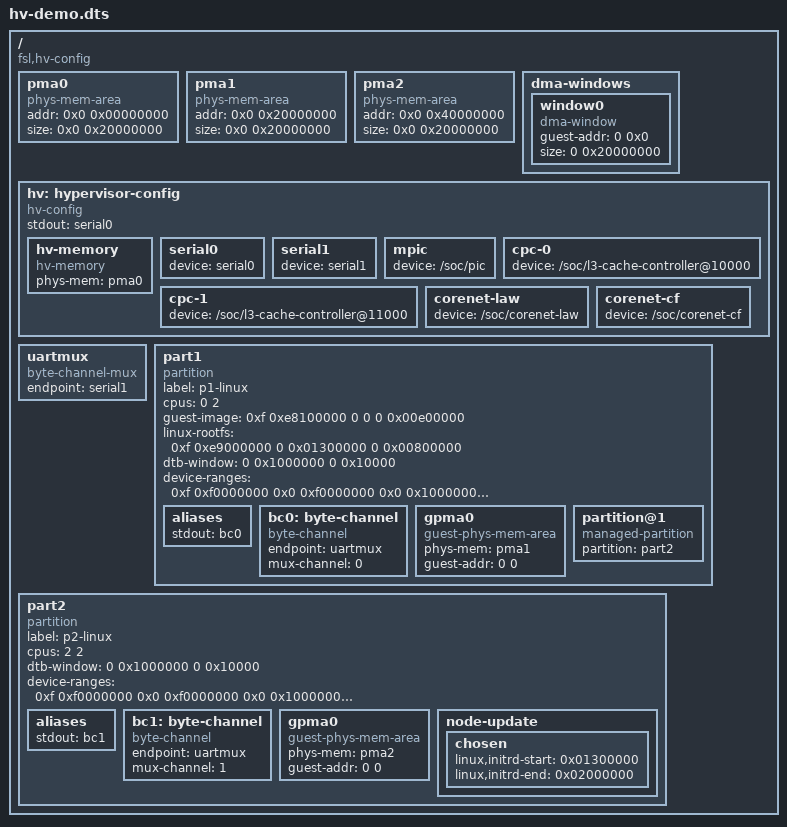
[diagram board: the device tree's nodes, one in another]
/*
 * Copyright (C) 2008,2009 Freescale Semiconductor, Inc.
 *
 * Redistribution and use in source and binary forms, with or without
 * modification, are permitted provided that the following conditions
 * are met:
 * 1. Redistributions of source code must retain the above copyright
 *    notice, this list of conditions and the following disclaimer.
 * 2. Redistributions in binary form must reproduce the above copyright
 *    notice, this list of conditions and the following disclaimer in the
 *    documentation and/or other materials provided with the distribution.
 *
 * THIS SOFTWARE IS PROVIDED BY THE AUTHOR "AS IS" AND ANY EXPRESS OR
 * IMPLIED WARRANTIES, INCLUDING, BUT NOT LIMITED TO, THE IMPLIED WARRANTIES
 * OF MERCHANTABILITY AND FITNESS FOR A PARTICULAR PURPOSE ARE DISCLAIMED.  IN
 * NO EVENT SHALL THE AUTHOR BE LIABLE FOR ANY DIRECT, INDIRECT, INCIDENTAL,
 * SPECIAL, EXEMPLARY, OR CONSEQUENTIAL DAMAGES (INCLUDING, BUT NOT LIMITED
 * TO, PROCUREMENT OF SUBSTITUTE GOODS OR SERVICES; LOSS OF USE, DATA, OR
 * PROFITS; OR BUSINESS INTERRUPTION) HOWEVER CAUSED AND ON ANY THEORY OF
 * LIABILITY, WHETHER IN CONTRACT, STRICT LIABILITY, OR TORT (INCLUDING
 * NEGLIGENCE OR OTHERWISE) ARISING IN ANY WAY OUT OF THE USE OF THIS
 * SOFTWARE, EVEN IF ADVISED OF THE POSSIBILITY OF SUCH DAMAGE.
 */

/dts-v1/;

/ {
	compatible = "fsl,hv-config";

	// =====================================================
	// Physical Memory Areas
	// =====================================================
	pma0:pma0 {
		compatible = "phys-mem-area";
		addr = <0x0 0x00000000>;
		size = <0x0 0x20000000>;  // 512MB
	};

	pma1:pma1 {
		compatible = "phys-mem-area";
		addr = <0x0 0x20000000>;
		size = <0x0 0x20000000>;  // 512MB
	};

	pma2:pma2 {
		compatible = "phys-mem-area";
		addr = <0x0 0x40000000>;
		size = <0x0 0x20000000>;  // 512MB
	};

	dma-windows {
		window0: window0 {
			compatible = "dma-window";
			guest-addr = <0 0x0>;
			size = <0 0x20000000>;
		};
	};

	// =====================================================
	// Hypervisor Config
	// =====================================================
	hv:hypervisor-config {
		compatible = "hv-config";
		stdout = <&serial0>;

		hv-memory {
			compatible = "hv-memory";
			phys-mem = <&pma0>;
		};

		serial0:serial0 {
			device = "serial0";
		};

		serial1:serial1 {
			device = "serial1";
		};

		mpic {
			device = "/soc/pic";
		};

		cpc-0 {
			device = "/soc/l3-cache-controller@10000";
		};

		cpc-1 {
			device = "/soc/l3-cache-controller@11000";
		};

		corenet-law {
			device = "/soc/corenet-law";
		};

		corenet-cf {
			device = "/soc/corenet-cf";
		};
	};

	uartmux: uartmux {
		compatible = "byte-channel-mux";
		endpoint = <&serial1>;
	};

	// =====================================================
	// Partition 1
	// =====================================================
	part1 {
		compatible = "partition";
		label = "p1-linux";
		cpus = <0 2>;
		guest-image = <0xf 0xe8100000 0 0 0 0x00e00000>;
		linux-rootfs = <0xf 0xe9000000 0 0x01300000 0 0x00800000>;
		dtb-window = <0 0x1000000 0 0x10000>;

		device-ranges = <0xf 0xf0000000 0x0 0xf0000000 0x0 0x10000000
				 0xc 0x00000000 0x0 0x80000000 0x0 0x20000000
				 0xc 0x20000000 0x0 0xa0000000 0x0 0x20000000
				 0xc 0x40000000 0x0 0xc0000000 0x0 0x20000000>;

		aliases {
			stdout = <&bc0>;
		};

		bc0: byte-channel {
			compatible = "byte-channel";
			endpoint = <&uartmux>;
			mux-channel = <0>;
		};

		gpma0 {
			compatible = "guest-phys-mem-area";
			phys-mem = <&pma1>;
			guest-addr = <0 0>;
		};

		partition@1 {
			compatible = "managed-partition";
			partition = <&part2>;
		};
	};

	// =====================================================
	// Partition 2
	// =====================================================
	part2:part2 {
		compatible = "partition";
		label = "p2-linux";
		cpus = <2 2>;
		dtb-window = <0 0x1000000 0 0x10000>;

		device-ranges = <0xf 0xf0000000 0x0 0xf0000000 0x0 0x10000000
				 0xc 0x00000000 0x0 0x80000000 0x0 0x20000000
				 0xc 0x20000000 0x0 0xa0000000 0x0 0x20000000
				 0xc 0x40000000 0x0 0xc0000000 0x0 0x20000000>;

		aliases {
			stdout = <&bc1>;
		};

		bc1: byte-channel {
			compatible = "byte-channel";
			endpoint = <&uartmux>;
			mux-channel = <1>;
		};

		gpma0 {
			compatible = "guest-phys-mem-area";
			phys-mem = <&pma2>;
			guest-addr = <0 0>;
		};

		/* Currently, the hypervisor does not support updating the
		 * chosen node based on images loaded via partman.  This is
		 * because there's no mechanism for partman to tell the
		 * hypervisor that a particular image is a root file system.
		 * So we need to hard-code the memory ranges used for the
		 * rootfs here.  To load the rootfs, use:
		 * "partman -l -a X ...", where X is the value of
		 * linux,initrd-start below.
		 */
		node-update {
			chosen {
				linux,initrd-start = <0x01300000>;
				linux,initrd-end = <0x02000000>;
			};
		};
	};
};
